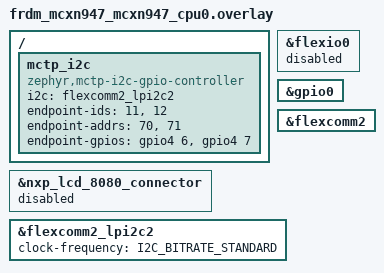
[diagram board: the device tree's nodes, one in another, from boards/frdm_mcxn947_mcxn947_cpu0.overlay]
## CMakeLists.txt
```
cmake_minimum_required(VERSION 3.20.0)

find_package(Zephyr REQUIRED HINTS $ENV{ZEPHYR_BASE})

project(sensor_hub_sub)

target_sources(app PRIVATE src/main.c)
```

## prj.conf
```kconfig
CONFIG_STDOUT_CONSOLE=y
CONFIG_POSIX_API=y
CONFIG_TEST_RANDOM_GENERATOR=y
CONFIG_HEAP_MEM_POOL_SIZE=8192
CONFIG_MCTP_HEAP_SIZE=8192
CONFIG_MAIN_STACK_SIZE=4096
CONFIG_LOG=y

CONFIG_SENSOR=y
CONFIG_SENSOR_ASYNC_API=y

CONFIG_ZENOH_PICO=y
CONFIG_ZENOH_PICO_LINK_MCTP=y
CONFIG_ZENOH_PICO_QUERYABLE=y
CONFIG_ZENOH_PICO_SUBSCRIPTION=y
CONFIG_ZENOH_PICO_MULTI_THREAD=y

CONFIG_I2C=y
CONFIG_I2C_RTIO=y
CONFIG_I2C_MCUX_LPI2C_BUS_RECOVERY=y

CONFIG_MCTP=y
CONFIG_MCTP_I2C_GPIO_CONTROLLER=y
CONFIG_MCTP_LOG_LEVEL_DBG=y
CONFIG_MCTP_ENDPOINT_ID=20
```

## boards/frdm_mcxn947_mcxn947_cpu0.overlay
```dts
#include <zephyr/dt-bindings/gpio/gpio.h>

/* Sets up I2C and a GPIO on JP8 to use as our i2c bus for MCTP */


&nxp_lcd_8080_connector {
	status = "disabled";
};

&flexio0 {
	status = "disabled";
};

&gpio0 {
	status = "okay";
};

&flexcomm2 {
	status = "okay";
};

&flexcomm2_lpi2c2 {
	status = "okay";
	clock-frequency = <I2C_BITRATE_STANDARD>;
};

/ {
	mctp_i2c: mctp_i2c {
		compatible = "zephyr,mctp-i2c-gpio-controller";
		i2c = <&flexcomm2_lpi2c2>;
		endpoint-ids = <11>, <12>;
		endpoint-addrs = <70>, <71>;
		endpoint-gpios = <&gpio4 6 GPIO_ACTIVE_HIGH>, <&gpio4 7 GPIO_ACTIVE_HIGH>;
	};
};
```

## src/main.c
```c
/*
 * Copyright (c) 2025 Intel Corporation
 *
 * SPDX-License-Identifier: Apache-2.0
 */

#include <stdlib.h>
#include <stdio.h>
#include <assert.h>
#include <unistd.h>
#include <zephyr/types.h>
#include <zephyr/kernel.h>
#include <zephyr/pmci/mctp/mctp.h>
#include <libmctp.h>
#include <zenoh-pico.h>

#include <zephyr/pmci/mctp/mctp_i2c_gpio_target.h>

#include <zephyr/logging/log.h>
LOG_MODULE_REGISTER(sensor_hub_sub);

MCTP_I2C_GPIO_CONTROLLER_DT_DEFINE(mctp_i2c_ctrl, DT_NODELABEL(mctp_i2c));

#define MODE "peer"
#define LOCATOR "mctp/11#"

#define KEYEXPR "demo/example/**"

void data_handler(z_loaned_sample_t *sample, void *arg) {
    z_view_string_t keystr;
    z_keyexpr_as_view_string(z_sample_keyexpr(sample), &keystr);
    z_owned_string_t value;
    z_bytes_to_string(z_sample_payload(sample), &value);
    LOG_INF(" >> [Subscriber handler] Received ('%.*s': '%.*s')", (int)z_string_len(z_loan(keystr)),
           z_string_data(z_loan(keystr)), (int)z_string_len(z_loan(value)), z_string_data(z_loan(value)));
    z_drop(z_move(value));
}

int main(int argc, char **argv) {
    int rc;

    
    LOG_INF("Sensor Hub Sub: MCTP Endpoint ID[%d] on Board [%s]", CONFIG_MCTP_ENDPOINT_ID, CONFIG_BOARD_TARGET);
    zephyr_mctp_register_bus(&mctp_i2c_ctrl.binding);

    // Initialize Zenoh Session and other parameters
    z_owned_config_t config;
    z_config_default(&config);
    zp_config_insert(z_loan_mut(config), Z_CONFIG_MODE_KEY, MODE);
    if (strcmp(LOCATOR, "") != 0) {
    
	    zp_config_insert(z_loan_mut(config), Z_CONFIG_LISTEN_KEY, LOCATOR);
    }
    // Open Zenoh session
    LOG_INF("Opening Zenoh Session...");
    z_owned_session_t s;
    while (z_open(&s, z_move(config), NULL) < 0) {
        LOG_INF("Unable to open session, retrying in a few...\n");
        k_msleep(5000);
    }
    LOG_INF("Starting read+lease tasks");
    // Start the receive and the session lease loop for zenoh-pico
    zp_start_read_task(z_loan_mut(s), NULL);
    zp_start_lease_task(z_loan_mut(s), NULL);
    LOG_INF("Declaring Subscriber on '%s'...", KEYEXPR);
    z_owned_closure_sample_t callback;
    z_closure(&callback, data_handler, NULL, NULL);
    z_view_keyexpr_t ke;
    z_view_keyexpr_from_str_unchecked(&ke, KEYEXPR);
    z_owned_subscriber_t sub;
    if (z_declare_subscriber(z_loan(s), &sub, z_loan(ke), z_move(callback), NULL) < 0) {
        LOG_ERR("Unable to declare subscriber.");
        return -1;
    }
    LOG_INF("Looping for eternity!");
    while (1) {
        sleep(1);
    }
    LOG_INF("Closing Zenoh Session...");
    z_drop(z_move(sub));
    z_drop(z_move(s));
    LOG_INF("Done!");
    return rc;
}
```
